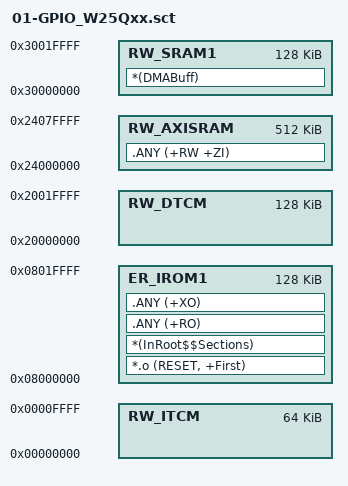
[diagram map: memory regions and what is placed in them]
; *************************************************************
; *** Scatter-Loading Description File generated by uVision ***
; *************************************************************

LR_IROM1 0x08000000 0x00020000  {    ; load region size_region
  ER_IROM1 0x08000000 0x00020000  {  ; load address = execution address
   *.o (RESET, +First)
   *(InRoot$$Sections)
   .ANY (+RO)
   .ANY (+XO)
  }
  RW_AXISRAM 0x24000000 0x00080000  {
   .ANY (+RW +ZI)
  }
  RW_SRAM1 0x30000000 0x00020000	{
   *(DMABuff)
  }
  RW_ITCM 0x00000000 0x00010000		{
  }
  RW_DTCM 0x20000000 0x00020000  {  ; RW data
  }
}

